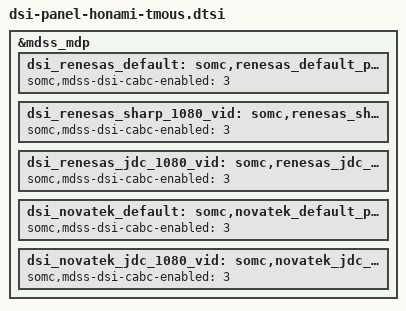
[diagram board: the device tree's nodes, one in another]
/* arch/arm/boot/dts/dsi-panel-honami-tmous.dtsi
 *
 * Copyright (C) 2014 Sony Mobile Communications AB.
 *
 * This program is free software; you can redistribute it and/or modify
 * it under the terms of the GNU General Public License version 2 and
 * only version 2 as published by the Free Software Foundation.
 *
 * This program is distributed in the hope that it will be useful,
 * but WITHOUT ANY WARRANTY; without even the implied warranty of
 * MERCHANTABILITY or FITNESS FOR A PARTICULAR PURPOSE.  See the
 * GNU General Public License for more details.
 */

&mdss_mdp {
	dsi_renesas_default: somc,renesas_default_panel {
		somc,mdss-dsi-cabc-enabled = <3>;
	};

	dsi_renesas_sharp_1080_vid: somc,renesas_sharp_1080p_panel {
		somc,mdss-dsi-cabc-enabled = <3>;
	};

	dsi_renesas_jdc_1080_vid: somc,renesas_jdc_1080p_panel {
		somc,mdss-dsi-cabc-enabled = <3>;
	};

	dsi_novatek_default: somc,novatek_default_panel {
		somc,mdss-dsi-cabc-enabled = <3>;
	};

	dsi_novatek_jdc_1080_vid: somc,novatek_jdc_1080p_panel {
		somc,mdss-dsi-cabc-enabled = <3>;
	};
};
